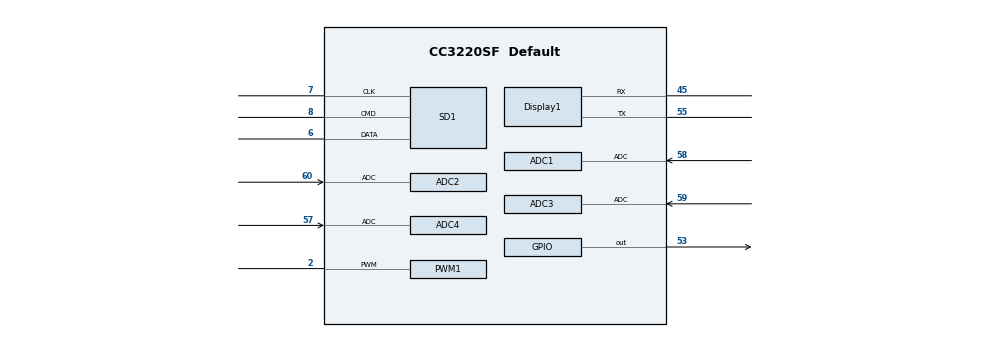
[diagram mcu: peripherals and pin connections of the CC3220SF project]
/**
 * @cliArgs --device "CC3220SF" --package "Default" --part "Default" --product "simplelink_cc32xx_sdk@5.10.00.02"
 * @versions {"data":"2021031521","timestamp":"2021031521","tool":"1.8.0+1863","templates":null}
 */

/**
 * Import the modules used in this configuration.
 */
const DriverLib      = scripting.addModule("/ti/devices/DriverLib");
const Display        = scripting.addModule("/ti/display/Display");
const Display1       = Display.addInstance();
const ADC            = scripting.addModule("/ti/drivers/ADC", {}, false);
const ADC1           = ADC.addInstance();
const ADC2           = ADC.addInstance();
const ADC3           = ADC.addInstance();
const ADC4           = ADC.addInstance();
const Board          = scripting.addModule("/ti/drivers/Board");
const Crypto         = scripting.addModule("/ti/drivers/Crypto");
const Crypto1        = Crypto.addInstance();
const DMA            = scripting.addModule("/ti/drivers/DMA");
const GPIO           = scripting.addModule("/ti/drivers/GPIO", {}, false);
const GPIO1          = GPIO.addInstance();
const PWM            = scripting.addModule("/ti/drivers/PWM", {}, false);
const PWM1           = PWM.addInstance();
const Power          = scripting.addModule("/ti/drivers/Power");
const RTOS           = scripting.addModule("/ti/drivers/RTOS");
const SD             = scripting.addModule("/ti/drivers/SD", {}, false);
const SD1            = SD.addInstance();
const SPI            = scripting.addModule("/ti/drivers/SPI");
const Timer          = scripting.addModule("/ti/drivers/Timer");
const Timer1         = Timer.addInstance();
const Timer2         = Timer.addInstance();
const Timer3         = Timer.addInstance();
const Timer4         = Timer.addInstance();
const Watchdog       = scripting.addModule("/ti/drivers/Watchdog");
const Watchdog1      = Watchdog.addInstance();
const SimpleLinkWifi = scripting.addModule("/ti/drivers/net/wifi/SimpleLinkWifi");
const atcmd          = scripting.addModule("/ti/drivers/net/wifi/atcmd", {}, false);
const atcmd1         = atcmd.addInstance();
const net_utils      = scripting.addModule("/ti/drivers/net/wifi/net_utils", {}, false);
const net_utils1     = net_utils.addInstance();
const HTTPClient     = scripting.addModule("/ti/net/HTTPClient", {}, false);
const HTTPClient1    = HTTPClient.addInstance();
const HTTPServer     = scripting.addModule("/ti/net/HTTPServer", {}, false);
const HTTPServer1    = HTTPServer.addInstance();
const MQTT           = scripting.addModule("/ti/net/MQTT", {}, false);
const MQTT1          = MQTT.addInstance();
const SNTP           = scripting.addModule("/ti/net/SNTP");
const SlNet          = scripting.addModule("/ti/net/SlNet");
const SlNet1         = SlNet.addInstance();
const JSON           = scripting.addModule("/ti/utils/JSON");

/**
 * Write custom configuration values to the imported modules.
 */
Display1.$name                          = "CONFIG_Display_0";
Display1.uart.$name                     = "CONFIG_UART_0";
Display1.uart.useDMA                    = true;
Display1.uart.uart.$assign              = "UART0";
Display1.uart.uart.txPin.$assign        = "55";
Display1.uart.uart.rxPin.$assign        = "45";
Display1.uart.uart.txDmaChannel.$assign = "UDMA_CH9";
Display1.uart.uart.rxDmaChannel.$assign = "UDMA_CH8";

ADC1.$name              = "CONFIG_ADC_0";
ADC1.adc.$assign        = "ADC0";
ADC1.adc.adcPin.$assign = "58";

ADC2.$name              = "CONFIG_ADC_1";
ADC2.adc.$assign        = "ADC0";
ADC2.adc.adcPin.$assign = "60";

ADC3.$name              = "CONFIG_ADC_2";
ADC3.adc.$assign        = "ADC0";
ADC3.adc.adcPin.$assign = "59";

ADC4.$name              = "CONFIG_ADC_3";
ADC4.adc.$assign        = "ADC0";
ADC4.adc.adcPin.$assign = "57";

Crypto1.$name = "CONFIG_Crypto_0";

GPIO1.$name           = "CONFIG_GPIO_ena";
GPIO1.mode            = "Output";
GPIO1.gpioPin.$assign = "53";

PWM1.$name                = "CONFIG_PWM_0";
PWM1.timer.$assign        = "Timer3";
PWM1.timer.pwmPin.$assign = "2";

Power.ioRetentionShutdown = ["GRP_1"];
Power.parkPins.$name      = "ti_drivers_power_PowerCC32XXPins0";

SD1.useFatFS                    = true;
SD1.$name                       = "CONFIG_SDFatFS_0";
SD1.sdHost.$assign              = "SDHost0";
SD1.sdHost.clkPin.$assign       = "7";
SD1.sdHost.cmdPin.$assign       = "8";
SD1.sdHost.dataPin.$assign      = "6";
SD1.sdHost.dmaTxChannel.$assign = "UDMA_CH15";
SD1.sdHost.dmaRxChannel.$assign = "UDMA_CH14";

Timer1.$name         = "CONFIG_TIMER_0";
Timer1.timerType     = "32 Bits";
Timer1.timer.$assign = "Timer0";

Timer2.$name         = "CONFIG_TIMER_1";
Timer2.timer.$assign = "Timer1";

Timer3.$name         = "CONFIG_TIMER_2";
Timer3.timer.$assign = "Timer1";

Timer4.$name         = "CONFIG_TIMER_3";
Timer4.timerType     = "32 Bits";
Timer4.timer.$assign = "Timer2";

Watchdog1.$name            = "CONFIG_WATCHDOG_0";
Watchdog1.watchdog.$assign = "WATCHDOG0";

atcmd1.$name = "CONFIG_ATCMD_0";

net_utils1.$name = "CONFIG_NET_UTILS_0";

HTTPClient1.$name = "CONFIG_HTTPCLIENT_0";

HTTPServer1.$name = "CONFIG_HTTPSERVER_0";

MQTT1.$name = "CONFIG_MQTT_0";

SlNet1.$name  = "CONFIG_SLNET";
SlNet1.ifName = "CC32xx";
